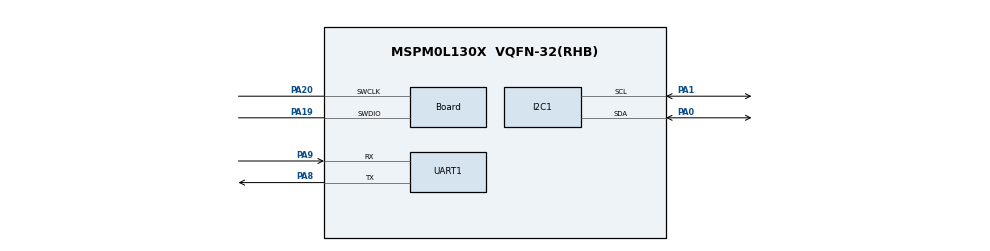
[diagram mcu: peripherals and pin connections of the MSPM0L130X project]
/**
 * @cliArgs --device "MSPM0L130X" --part "Default" --package "VQFN-32(RHB)" --product "mspm0_sdk@2.02.00.05"
 * @versions {"tool":"1.21.0+3721"}
 */

/**
 * Import the modules used in this configuration.
 */
const Board = scripting.addModule("/ti/driverlib/Board");
const GPIO  = scripting.addModule("/ti/driverlib/GPIO", {}, false);
const GPIO1 = GPIO.addInstance();
const GPIO2 = GPIO.addInstance();
const I2C   = scripting.addModule("/ti/driverlib/I2C", {}, false);
const I2C1  = I2C.addInstance();
const UART  = scripting.addModule("/ti/driverlib/UART", {}, false);
const UART1 = UART.addInstance();

/**
 * Write custom configuration values to the imported modules.
 */
Board.configureUnused             = true;
Board.peripheral.$assign          = "DEBUGSS";
Board.peripheral.swclkPin.$assign = "PA20";
Board.peripheral.swdioPin.$assign = "PA19";

GPIO1.$name                         = "GPIO_LEDS";
GPIO1.port                          = "PORTA";
GPIO1.associatedPins.create(3);
GPIO1.associatedPins[0].$name       = "GREEN";
GPIO1.associatedPins[0].assignedPin = "13";
GPIO1.associatedPins[1].$name       = "RED";
GPIO1.associatedPins[1].assignedPin = "26";
GPIO1.associatedPins[2].$name       = "BLUE";
GPIO1.associatedPins[2].assignedPin = "27";

GPIO2.$name                          = "GEN";
GPIO2.associatedPins[0].assignedPort = "PORTA";
GPIO2.associatedPins[0].$name        = "OUT";
GPIO2.associatedPins[0].assignedPin  = "3";

I2C1.$name                             = "I2C";
I2C1.basicEnableController             = true;
I2C1.basicControllerBusSpeed           = 400000;
I2C1.advAnalogGlitchFilter             = "DISABLED";
I2C1.advControllerTXFIFOTRIG           = "BYTES_1";
I2C1.peripheral.$assign                = "I2C0";
I2C1.peripheral.sdaPin.$assign         = "PA0";
I2C1.peripheral.sclPin.$assign         = "PA1";
I2C1.sdaPinConfig.$name                = "ti_driverlib_gpio_GPIOPinGeneric0";
I2C1.sdaPinConfig.hideOutputInversion  = scripting.forceWrite(false);
I2C1.sdaPinConfig.onlyInternalResistor = scripting.forceWrite(false);
I2C1.sdaPinConfig.passedPeripheralType = scripting.forceWrite("Digital");
I2C1.sclPinConfig.$name                = "ti_driverlib_gpio_GPIOPinGeneric1";
I2C1.sclPinConfig.hideOutputInversion  = scripting.forceWrite(false);
I2C1.sclPinConfig.onlyInternalResistor = scripting.forceWrite(false);
I2C1.sclPinConfig.passedPeripheralType = scripting.forceWrite("Digital");

const SYSCTL       = scripting.addModule("/ti/driverlib/SYSCTL", {}, false);
SYSCTL.clockTreeEn = true;

UART1.$name                        = "UART_0";
UART1.enableFIFO                   = true;
UART1.targetBaudRate               = 115200;
UART1.peripheral.$assign           = "UART0";
UART1.peripheral.rxPin.$assign     = "PA9";
UART1.peripheral.txPin.$assign     = "PA8";
UART1.txPinConfig.$name            = "ti_driverlib_gpio_GPIOPinGeneric2";
UART1.rxPinConfig.$name            = "ti_driverlib_gpio_GPIOPinGeneric3";
UART1.rxPinConfig.enableConfig     = true;
UART1.rxPinConfig.internalResistor = "PULL_UP";

/**
 * Pinmux solution for unlocked pins/peripherals. This ensures that minor changes to the automatic solver in a future
 * version of the tool will not impact the pinmux you originally saw.  These lines can be completely deleted in order to
 * re-solve from scratch.
 */
GPIO1.associatedPins[0].pin.$suggestSolution = "PA13";
GPIO1.associatedPins[1].pin.$suggestSolution = "PA26";
GPIO1.associatedPins[2].pin.$suggestSolution = "PA27";
GPIO2.associatedPins[0].pin.$suggestSolution = "PA3";
